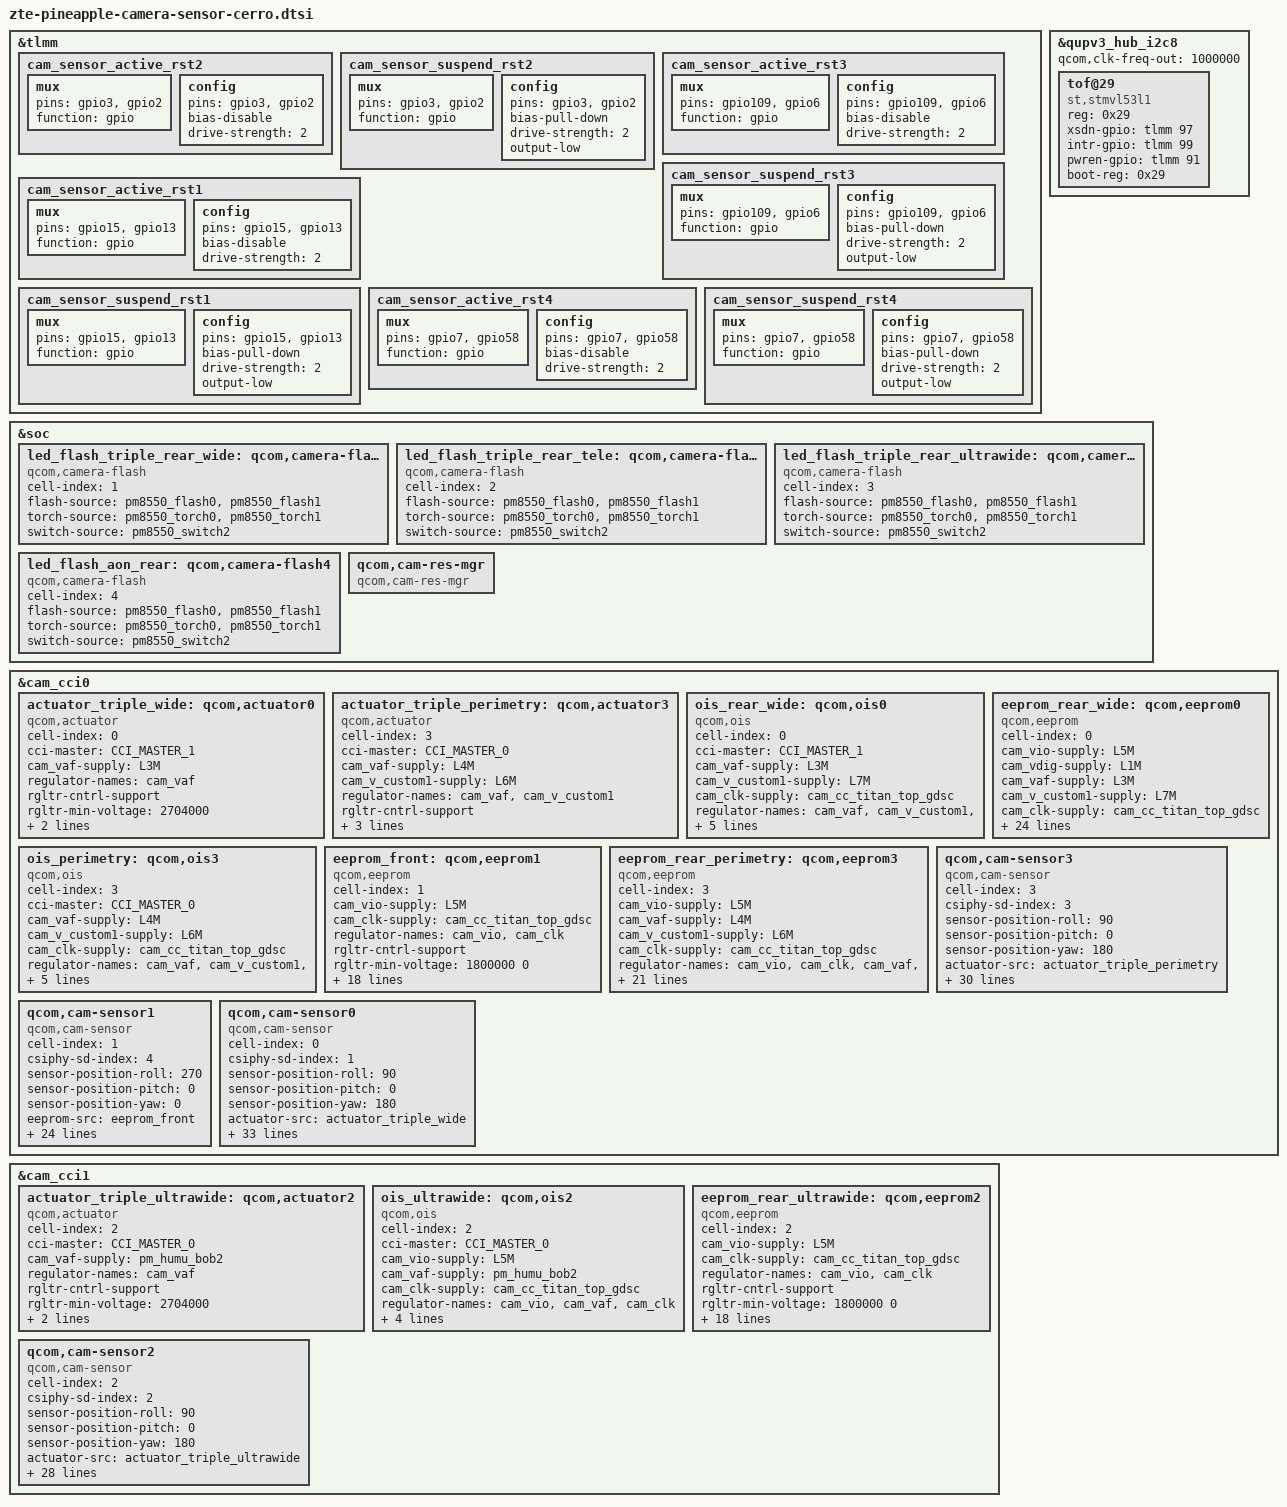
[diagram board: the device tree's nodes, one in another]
#include <dt-bindings/msm-camera.h>
&tlmm {
	cam_sensor_active_rst2: cam_sensor_active_rst2 {
		/* RESET 2 */
		mux {
			pins = "gpio3", "gpio2";
			function = "gpio";
		};

		config {
			pins = "gpio3", "gpio2";
			bias-disable; /* No PULL */
			drive-strength = <2>; /* 2 MA */
		};
	};

	cam_sensor_suspend_rst2: cam_sensor_suspend_rst2 {
		/* RESET 2 */
		mux {
			pins = "gpio3", "gpio2";
			function = "gpio";
		};

		config {
			pins = "gpio3", "gpio2";
			bias-pull-down; /* PULL DOWN */
			drive-strength = <2>; /* 2 MA */
			output-low;
		};
	};

	cam_sensor_active_rst3: cam_sensor_active_rst3 {
		/* RESET 3 */
		mux {
			pins = "gpio109", "gpio6";
			function = "gpio";
		};

		config {
			pins = "gpio109", "gpio6";
			bias-disable; /* No PULL */
			drive-strength = <2>; /* 2 MA */
		};
	};

	cam_sensor_suspend_rst3: cam_sensor_suspend_rst3 {
		/* RESET 3 */
		mux {
			pins = "gpio109", "gpio6";
			function = "gpio";
		};

		config {
			pins = "gpio109", "gpio6";
			bias-pull-down; /* PULL DOWN */
			drive-strength = <2>; /* 2 MA */
			output-low;
		};
	};

	cam_sensor_active_rst1: cam_sensor_active_rst1 {
		/* RESET 1 */
		mux {
			pins = "gpio15", "gpio13";
			function = "gpio";
		};

		config {
			pins = "gpio15", "gpio13";
			bias-disable; /* No PULL */
			drive-strength = <2>; /* 2 MA */
		};
	};

	cam_sensor_suspend_rst1: cam_sensor_suspend_rst1 {
		/* RESET 1 */
		mux {
			pins = "gpio15", "gpio13";
			function = "gpio";
		};

		config {
			pins = "gpio15", "gpio13";
			bias-pull-down; /* PULL DOWN */
			drive-strength = <2>; /* 2 MA */
			output-low;
		};
	};

	cam_sensor_active_rst4: cam_sensor_active_rst4 {
		/* RESET 0 */
		mux {
			pins = "gpio7", "gpio58";
			function = "gpio";
		};

		config {
			pins = "gpio7", "gpio58";
			bias-disable; /* No PULL */
			drive-strength = <2>; /* 2 MA */
		};
	};

	cam_sensor_suspend_rst4: cam_sensor_suspend_rst4 {
		/* RESET 0 */
		mux {
			pins = "gpio7", "gpio58";
			function = "gpio";
		};

		config {
			pins = "gpio7", "gpio58";
			bias-pull-down; /* PULL DOWN */
			drive-strength = <2>; /* 2 MA */
			output-low;
		};
	};
};

&qupv3_hub_i2c8 {
	status = "ok";
	qcom,clk-freq-out = <1000000>;
	tof@29 {
		compatible = "st,stmvl53l1";
		reg = <0x29>;
		xsdn-gpio = <&tlmm 97 0>;
		intr-gpio = <&tlmm 99 0>;
		pwren-gpio = <&tlmm 91 0>;
		boot-reg = <0x29>;
		status = "ok";
	};
};

&soc {
	led_flash_triple_rear_wide: qcom,camera-flash1 {
		cell-index = <1>;
		compatible = "qcom,camera-flash";
		flash-source = <&pm8550_flash0 &pm8550_flash1>;
		torch-source = <&pm8550_torch0 &pm8550_torch1>;
		switch-source = <&pm8550_switch2>;
		status = "ok";
	};

	led_flash_triple_rear_tele: qcom,camera-flash2 {
		cell-index = <2>;
		compatible = "qcom,camera-flash";
		flash-source = <&pm8550_flash0 &pm8550_flash1>;
		torch-source = <&pm8550_torch0 &pm8550_torch1>;
		switch-source = <&pm8550_switch2>;
		status = "ok";
	};

	led_flash_triple_rear_ultrawide: qcom,camera-flash3 {
		cell-index = <3>;
		compatible = "qcom,camera-flash";
		flash-source = <&pm8550_flash0 &pm8550_flash1>;
		torch-source = <&pm8550_torch0 &pm8550_torch1>;
		switch-source = <&pm8550_switch2>;
		status = "ok";
	};

	led_flash_aon_rear: qcom,camera-flash4 {
		cell-index = <4>;
		compatible = "qcom,camera-flash";
		flash-source = <&pm8550_flash0 &pm8550_flash1>;
		torch-source = <&pm8550_torch0 &pm8550_torch1>;
		switch-source = <&pm8550_switch2>;
		status = "ok";
	};

	qcom,cam-res-mgr {
		compatible = "qcom,cam-res-mgr";
		status = "ok";
	};
};

&cam_cci0 {
	actuator_triple_wide: qcom,actuator0 {
		cell-index = <0>;
		compatible = "qcom,actuator";
		cci-master = <CCI_MASTER_1>;
		cam_vaf-supply = <&L3M>;
		regulator-names = "cam_vaf";
		rgltr-cntrl-support;
		rgltr-min-voltage = <2704000>;
		rgltr-max-voltage = <3000000>;
		rgltr-load-current = <103000>;
	};

	actuator_triple_perimetry: qcom,actuator3 {
		cell-index = <3>;
		compatible = "qcom,actuator";
		cci-master = <CCI_MASTER_0>;
		cam_vaf-supply = <&L4M>;
		cam_v_custom1-supply = <&L6M>;
		regulator-names = "cam_vaf", "cam_v_custom1";
		rgltr-cntrl-support;
		rgltr-min-voltage = <2800000 2800000>;
		rgltr-max-voltage = <2800000 2800000>;
		rgltr-load-current = <103000 103000>;
	};

	ois_rear_wide: qcom,ois0 {
		cell-index = <0>;
		compatible = "qcom,ois";
		cci-master = <CCI_MASTER_1>;
		cam_vaf-supply = <&L3M>;
		cam_v_custom1-supply = <&L7M>;
		cam_clk-supply = <&cam_cc_titan_top_gdsc>;
		regulator-names = "cam_vaf", "cam_v_custom1", "cam_clk";
		rgltr-cntrl-support;
		rgltr-min-voltage = <2704000 2960000 0>;
		rgltr-max-voltage = <3000000 2960000 0>;
		rgltr-load-current = <103000 90000 0>;
	};

	ois_perimetry: qcom,ois3 {
		cell-index = <3>;
		compatible = "qcom,ois";
		cci-master = <CCI_MASTER_0>;
		cam_vaf-supply = <&L4M>;
		cam_v_custom1-supply = <&L6M>;
		cam_clk-supply = <&cam_cc_titan_top_gdsc>;
		regulator-names = "cam_vaf", "cam_v_custom1", "cam_clk";
		rgltr-cntrl-support;
		rgltr-min-voltage = <2800000 2800000 0>;
		rgltr-max-voltage = <2800000 2800000 0>;
		rgltr-load-current = <119000 119000 0>;
		status = "ok";
	};

	eeprom_rear_wide: qcom,eeprom0 {
		cell-index = <0>;
		compatible = "qcom,eeprom";
		cam_vio-supply = <&L5M>;
		cam_vdig-supply = <&L1M>;
		cam_vaf-supply = <&L3M>;
		cam_v_custom1-supply = <&L7M>;
		cam_clk-supply = <&cam_cc_titan_top_gdsc>;
		regulator-names = "cam_vio", "cam_vdig", "cam_vaf", "cam_v_custom1", "cam_clk";
		rgltr-cntrl-support;
		rgltr-min-voltage = <1800000 1104000 2704000 2960000 0>;
		rgltr-max-voltage = <1800000 1104000 3000000 2960000 0>;
		rgltr-load-current = <3500 140000 103000 90000 0>;
		gpio-no-mux = <0>;
		pinctrl-names = "cam_default", "cam_suspend";
		pinctrl-0 = <&cam_sensor_mclk1_active
				 &cam_sensor_active_rst1>;
		pinctrl-1 = <&cam_sensor_mclk1_suspend
				 &cam_sensor_suspend_rst1>;
		gpios = <&tlmm 101 0>,
			<&tlmm 15 0>,
			<&tlmm 13 0>;
		gpio-reset = <1>;
		gpio-custom1 = <2>;
		gpio-req-tbl-num = <0 1 2>;
		gpio-req-tbl-flags = <1 0 0>;
		gpio-req-tbl-label = "CAMIF_MCLK1",
					"CAM_RESET1",
					"CAM_VANA1";
		cci-master = <CCI_MASTER_1>;
		clocks = <&camcc CAM_CC_MCLK1_CLK>;
		clock-names = "cam_clk";
		clock-cntl-level = "nominal";
		clock-rates = <24000000>;
		status = "ok";
	};

	eeprom_front: qcom,eeprom1 {
		cell-index = <1>;
		compatible = "qcom,eeprom";
		cam_vio-supply = <&L5M>;
		cam_clk-supply = <&cam_cc_titan_top_gdsc>;
		regulator-names = "cam_vio", "cam_clk";
		rgltr-cntrl-support;
		rgltr-min-voltage = <1800000 0>;
		rgltr-max-voltage = <1800000 0>;
		rgltr-load-current = <6000 0>;
		gpio-no-mux = <0>;
		pinctrl-names = "cam_default", "cam_suspend";
		pinctrl-0 = <&cam_sensor_mclk4_active
				 &cam_sensor_active_rst4>;
		pinctrl-1 = <&cam_sensor_mclk4_suspend
				 &cam_sensor_suspend_rst4>;
		gpios = <&tlmm 104 0>,
			<&tlmm 7 0>,
			<&tlmm 58 0>;
		gpio-reset = <1>;
		gpio-custom1 = <2>;
		gpio-req-tbl-num = <0 1 2>;
		gpio-req-tbl-flags = <1 0 0>;
		gpio-req-tbl-label = "CAMIF_MCLK4",
					"CAM_RESET4",
					"CAM_VANA4";
		cci-master = <CCI_MASTER_0>;
		clocks = <&camcc CAM_CC_MCLK4_CLK>;
		clock-names = "cam_clk";
		clock-cntl-level = "nominal";
		clock-rates = <24000000>;
		status = "ok";
	};

	eeprom_rear_perimetry: qcom,eeprom3 {
		cell-index = <3>;
		compatible = "qcom,eeprom";
		cam_vio-supply = <&L5M>;
		cam_vaf-supply = <&L4M>;
		cam_v_custom1-supply = <&L6M>;
		cam_clk-supply = <&cam_cc_titan_top_gdsc>;
		regulator-names = "cam_vio", "cam_clk" ,"cam_vaf", "cam_v_custom1";
		rgltr-cntrl-support;
		rgltr-min-voltage = <1800000 0 2704000 2800000>;
		rgltr-max-voltage = <1800000 0 3000000 2800000>;
		rgltr-load-current = <6000 0 103000 119000>;
		gpio-no-mux = <0>;
		pinctrl-names = "cam_default", "cam_suspend";
		pinctrl-0 = <&cam_sensor_mclk3_active
				 &cam_sensor_active_rst3>;
		pinctrl-1 = <&cam_sensor_mclk3_suspend
				 &cam_sensor_suspend_rst3>;
		gpios = <&tlmm 103 0>,
			<&tlmm 109 0>,
			<&tlmm 6 0>;
		gpio-reset = <1>;
		gpio-custom1 = <2>;
		gpio-req-tbl-num = <0 1 2>;
		gpio-req-tbl-flags = <1 0 0>;
		gpio-req-tbl-label = "CAMIF_MCLK3",
					"CAM_RESET3",
					"CAM_VANA3";
		cci-master = <CCI_MASTER_0>;
		clocks = <&camcc CAM_CC_MCLK3_CLK>;
		clock-names = "cam_clk";
		clock-cntl-level = "nominal";
		clock-rates = <24000000>;
		status = "ok";
	};

	qcom,cam-sensor3 {
		cell-index = <3>;
		compatible = "qcom,cam-sensor";
		csiphy-sd-index = <3>;
		sensor-position-roll = <90>;
		sensor-position-pitch = <0>;
		sensor-position-yaw = <180>;
		actuator-src = <&actuator_triple_perimetry>;
		eeprom-src = <&eeprom_rear_perimetry>;
		led-flash-src = <&led_flash_triple_rear_tele>;
		ois-src = <&ois_perimetry>;
		cam_vio-supply = <&L5M>;
		cam_vaf-supply = <&L4M>;
		cam_v_custom1-supply = <&L6M>;
		cam_clk-supply = <&cam_cc_titan_top_gdsc>;
		regulator-names = "cam_vio", "cam_clk" ,"cam_vaf", "cam_v_custom1";
		rgltr-cntrl-support;
		rgltr-min-voltage = <1800000 0 2704000 2800000>;
		rgltr-max-voltage = <1800000 0 3000000 2800000>;
		rgltr-load-current = <6000 0 103000 119000>;
		gpio-no-mux = <0>;
		pinctrl-names = "cam_default", "cam_suspend";
		pinctrl-0 = <&cam_sensor_mclk3_active
				 &cam_sensor_active_rst3>;
		pinctrl-1 = <&cam_sensor_mclk3_suspend
				 &cam_sensor_suspend_rst3>;
		gpios = <&tlmm 103 0>,
			<&tlmm 109 0>,
			<&tlmm 6 0>;
		gpio-reset = <1>;
		gpio-custom1 = <2>;
		gpio-req-tbl-num = <0 1 2>;
		gpio-req-tbl-flags = <1 0 0>;
		gpio-req-tbl-label = "CAMIF_MCLK3",
					"CAM_RESET3",
					"CAM_VANA3";
		cci-master = <CCI_MASTER_0>;
		clocks = <&camcc CAM_CC_MCLK3_CLK>;
		clock-names = "cam_clk";
		clock-cntl-level = "nominal";
		clock-rates = <24000000>;
		status = "ok";
		zte-tof-enable;
	};

	 qcom,cam-sensor1 {
		cell-index = <1>;
		compatible = "qcom,cam-sensor";
		csiphy-sd-index = <4>;
		sensor-position-roll = <270>;
		sensor-position-pitch = <0>;
		sensor-position-yaw = <0>;
		eeprom-src = <&eeprom_front>;
		cam_vio-supply = <&L5M>;
		cam_clk-supply = <&cam_cc_titan_top_gdsc>;
		regulator-names = "cam_vio", "cam_clk";
		rgltr-cntrl-support;
		rgltr-min-voltage = <1800000 0>;
		rgltr-max-voltage = <1800000 0>;
		rgltr-load-current = <6000 0>;
		gpio-no-mux = <0>;
		pinctrl-names = "cam_default", "cam_suspend";
		pinctrl-0 = <&cam_sensor_mclk4_active
				 &cam_sensor_active_rst4>;
		pinctrl-1 = <&cam_sensor_mclk4_suspend
				 &cam_sensor_suspend_rst4>;
		gpios = <&tlmm 104 0>,
			<&tlmm 7 0>,
			<&tlmm 58 0>;
		gpio-reset = <1>;
		gpio-custom1 = <2>;
		gpio-req-tbl-num = <0 1 2>;
		gpio-req-tbl-flags = <1 0 0>;
		gpio-req-tbl-label = "CAMIF_MCLK4",
					"CAM_RESET4",
					"CAM_VANA4";
		cci-master = <CCI_MASTER_0>;
		clocks = <&camcc CAM_CC_MCLK4_CLK>;
		clock-names = "cam_clk";
		clock-cntl-level = "nominal";
		clock-rates = <24000000>;
		status = "ok";
		zte-tof-enable;
	};

//main
	qcom,cam-sensor0 {
		cell-index = <0>;
		compatible = "qcom,cam-sensor";
		csiphy-sd-index = <1>;
		sensor-position-roll = <90>;
		sensor-position-pitch = <0>;
		sensor-position-yaw = <180>;
		actuator-src = <&actuator_triple_wide>;
		ois-src = <&ois_rear_wide>;
		eeprom-src = <&eeprom_rear_wide>;
		led-flash-src = <&led_flash_triple_rear_wide>;
		cam_vio-supply = <&L5M>;
		cam_vdig-supply = <&L1M>;
		cam_vaf-supply = <&L3M>;
		cam_v_custom1-supply = <&L7M>;
		cam_clk-supply = <&cam_cc_titan_top_gdsc>;
		regulator-names = "cam_vio", "cam_vdig", "cam_vaf", "cam_v_custom1", "cam_clk";
		rgltr-cntrl-support;
		rgltr-min-voltage = <1800000 1104000 2704000 2960000 0>;
		rgltr-max-voltage = <1800000 1104000 3000000 2960000 0>;
		rgltr-load-current = <3500 140000 103000 90000 0>;
		gpio-no-mux = <0>;
		pinctrl-names = "cam_default", "cam_suspend";
		pinctrl-0 = <&cam_sensor_mclk1_active
				 &cam_sensor_active_rst1>;
		pinctrl-1 = <&cam_sensor_mclk1_suspend
				 &cam_sensor_suspend_rst1>;
		gpios = <&tlmm 101 0>,
			<&tlmm 15 0>,
			<&tlmm 13 0>;
		gpio-reset = <1>;
		gpio-custom1 = <2>;
		gpio-req-tbl-num = <0 1 2>;
		gpio-req-tbl-flags = <1 0 0>;
		gpio-req-tbl-label = "CAMIF_MCLK1",
					"CAM_RESET1",
					"CAM_VANA1";
		cci-master = <CCI_MASTER_1>;
		clocks = <&camcc CAM_CC_MCLK1_CLK>;
		clock-names = "cam_clk";
		clock-cntl-level = "nominal";
		clock-rates = <24000000>;
		status = "ok";
		zte-tof-enable;
	};
};

&cam_cci1 {
	actuator_triple_ultrawide: qcom,actuator2 {
		cell-index = <2>;
		compatible = "qcom,actuator";
		cci-master = <CCI_MASTER_0>;
		cam_vaf-supply = <&pm_humu_bob2>;
		regulator-names = "cam_vaf";
		rgltr-cntrl-support;
		rgltr-min-voltage = <2704000>;
		rgltr-max-voltage = <3000000>;
		rgltr-load-current = <103000>;
	};

	ois_ultrawide: qcom,ois2 {
		cell-index = <2>;
		compatible = "qcom,ois";
		cci-master = <CCI_MASTER_0>;
		cam_vio-supply = <&L5M>;
		cam_vaf-supply = <&pm_humu_bob2>;
		cam_clk-supply = <&cam_cc_titan_top_gdsc>;
		regulator-names = "cam_vio","cam_vaf", "cam_clk";
		rgltr-cntrl-support;
		rgltr-min-voltage = <1800000 2704000 0>;
		rgltr-max-voltage = <1800000 3000000 0>;
		rgltr-load-current = <4000 103000 0>;
		status = "ok";
	};

	eeprom_rear_ultrawide: qcom,eeprom2 {
		cell-index = <2>;
		compatible = "qcom,eeprom";
		cam_vio-supply = <&L5M>;
		cam_clk-supply = <&cam_cc_titan_top_gdsc>;
		regulator-names = "cam_vio", "cam_clk";
		rgltr-cntrl-support;
		rgltr-min-voltage = <1800000 0>;
		rgltr-max-voltage = <1800000 0>;
		rgltr-load-current = <3500 0>;
		gpio-no-mux = <0>;
		pinctrl-names = "cam_default", "cam_suspend";
		pinctrl-0 = <&cam_sensor_mclk2_active
				 &cam_sensor_active_rst2>;
		pinctrl-1 = <&cam_sensor_mclk2_suspend
				 &cam_sensor_suspend_rst2>;
		gpios = <&tlmm 102 0>,
			<&tlmm 3 0>,
			<&tlmm 2 0>;
		gpio-reset = <1>;
		gpio-custom1 = <2>;
		gpio-req-tbl-num = <0 1 2>;
		gpio-req-tbl-flags = <1 0 0>;
		gpio-req-tbl-label = "CAMIF_MCLK2",
					"CAM_RESET2",
					"CAM_VANA2";
		cci-master = <CCI_MASTER_0>;
		clocks = <&camcc CAM_CC_MCLK2_CLK>;
		clock-names = "cam_clk";
		clock-cntl-level = "nominal";
		clock-rates = <24000000>;
		status = "ok";
	};

//ultrawide
	qcom,cam-sensor2 {
		cell-index = <2>;
		compatible = "qcom,cam-sensor";
		csiphy-sd-index = <2>;
		sensor-position-roll = <90>;
		sensor-position-pitch = <0>;
		sensor-position-yaw = <180>;
		actuator-src = <&actuator_triple_ultrawide>;
		eeprom-src = <&eeprom_rear_ultrawide>;
		led-flash-src = <&led_flash_triple_rear_ultrawide>;
		ois-src = <&ois_ultrawide>;
		cam_vio-supply = <&L5M>;
		cam_vdig-supply = <&L2M>;
		cam_clk-supply = <&cam_cc_titan_top_gdsc>;
		regulator-names = "cam_vio", "cam_vdig", "cam_clk";
		rgltr-cntrl-support;
		rgltr-min-voltage = <1800000 1056000 0>;
		rgltr-max-voltage = <1800000 1056000 0>;
		rgltr-load-current = <3500 140000 0>;
		gpio-no-mux = <0>;
		pinctrl-names = "cam_default", "cam_suspend";
		pinctrl-0 = <&cam_sensor_mclk2_active
				 &cam_sensor_active_rst2>;
		pinctrl-1 = <&cam_sensor_mclk2_suspend
				 &cam_sensor_suspend_rst2>;
		gpios = <&tlmm 102 0>,
			<&tlmm 3 0>,
			<&tlmm 2 0>;
		gpio-reset = <1>;
		gpio-custom1 = <2>;
		gpio-req-tbl-num = <0 1 2>;
		gpio-req-tbl-flags = <1 0 0>;
		gpio-req-tbl-label = "CAMIF_MCLK2",
					"CAM_RESET2",
					"CAM_VANA2";
		cci-master = <CCI_MASTER_0>;
		clocks = <&camcc CAM_CC_MCLK2_CLK>;
		clock-names = "cam_clk";
		clock-cntl-level = "nominal";
		clock-rates = <24000000>;
		status = "ok";
		zte-tof-enable;
	};
};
